# STM32H7A3 register map
File version: 3.4
CPU: CM7 r0p1, little endian, MPU, FPU, 4 interrupt priority bits
Registers are 32-bit, read-write, reset 0x0 unless marked. A register's access mark holds for its fields unless they carry their own. Offsets are from the block's base; [hi:lo] are bit positions; lines under a group give offsets from that group; {n}, {i} and the like mark numbered series; 'fields as' and 'values as' point back to an identical list.

## FLASH — Embedded Flash memory
Base 0x52002000
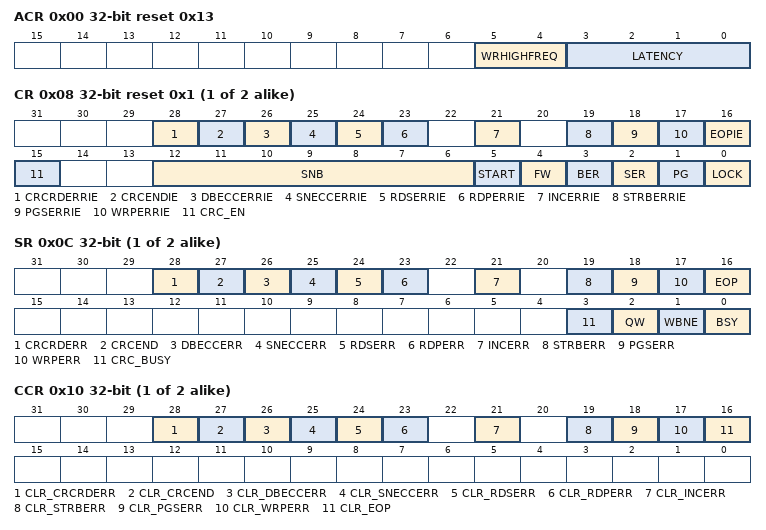
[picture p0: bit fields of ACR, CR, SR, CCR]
0x00 ACR reset 0x13 — Access control register
  [5:4] WRHIGHFREQ — Flash signal delay
  [3:0] LATENCY — Read latency
0x04 BANK{i} (i=1..2; step 0x100) group — Cluster BANK{i}, containing KEYR?, CR?, SR?, CCR?, PRAR_CUR?, PRAR_PRG?, SCAR_CUR?, SCAR_PRG?, WPSN_CUR?R, WPSN_PRG?R, CRCCR?, CRCSADD?R, CRCEADD?R, ECC_FA?R
  0x00 KEYR wo — FLASH key register for bank 1
    [31:0] KEY1R — Non-volatile memory bank 1 configuration access unlock key
  0x08 CR reset 0x1
    [28] CRCRDERRIE — Bank 1 CRC read error interrupt enable bit When CRCRDERRIE1 bit is set to 1, an interrupt is generated when a protected area (PCROP or secure-only) has been detected during the last CRC computation on bank 1. CRCRDERRIE1 can be programmed only when LOCK1 is cleared to 0.
    [27] CRCENDIE — Bank 1 CRC end of calculation interrupt enable bit When CRCENDIE1 bit is set to 1, an interrupt is generated when the CRC computation has completed on bank 1. CRCENDIE1 can be programmed only when LOCK1 is cleared to 0.
    [26] DBECCERRIE — Bank 1 ECC double detection error interrupt enable bit When DBECCERRIE1 bit is set to 1, an interrupt is generated when an ECC double detection error occurs during a read operation from bank 1. DBECCERRIE1 can be programmed only when LOCK1 is cleared to 0.
    [25] SNECCERRIE — Bank 1 ECC single correction error interrupt enable bit When SNECCERRIE1 bit is set to 1, an interrupt is generated when an ECC single correction error occurs during a read operation from bank 1. SNECCERRIE1 can be programmed only when LOCK1 is cleared to 0.
    [24] RDSERRIE — Bank 1 secure error interrupt enable bit When RDSERRIE1 bit is set to 1, an interrupt is generated when a secure error (access to a secure-only protected address) occurs during a read operation from bank 1. RDSERRIE1 can be programmed only when LOCK1 is cleared to 0.
    [23] RDPERRIE — Bank 1 read protection error interrupt enable bit When RDPERRIE1 bit is set to 1, an interrupt is generated when a read protection error occurs (access to an address protected by PCROP or by RDP level 1) during a read operation from bank 1. RDPERRIE1 can be programmed only when LOCK1 is cleared to 0.
    [21] INCERRIE — Bank 1 inconsistency error interrupt enable bit When INCERRIE1 bit is set to 1, an interrupt is generated when an inconsistency error occurs during a write operation to bank 1. INCERRIE1 can be programmed only when LOCK1 is cleared to 0.
    [19] STRBERRIE — Bank 1 strobe error interrupt enable bit When STRBERRIE1 bit is set to 1, an interrupt is generated when a strobe error occurs (the master programs several times the same byte in the write buffer) during a write operation to bank 1. STRBERRIE1 can be programmed only when LOCK1 is cleared to 0.
    [18] PGSERRIE — Bank 1 programming sequence error interrupt enable bit When PGSERRIE1 bit is set to 1, an interrupt is generated when a sequence error occurs during a program operation to bank 1. PGSERRIE1 can be programmed only when LOCK1 is cleared to 0.
    [17] WRPERRIE — Bank 1 write protection error interrupt enable bit When WRPERRIE1 bit is set to 1, an interrupt is generated when a protection error occurs during a program operation to bank 1. WRPERRIE1 can be programmed only when LOCK1 is cleared to 0.
    [16] EOPIE — Bank 1 end-of-program interrupt control bit Setting EOPIE1 bit to 1 enables the generation of an interrupt at the end of a program operation to bank 1. EOPIE1 can be programmed only when LOCK1 is cleared to 0.
    [15] CRC_EN — Bank 1 CRC control bit Setting CRC_EN bit to 1 enables the CRC calculation on bank 1. CRC_EN does not start CRC calculation but enables CRC configuration through FLASH_CRCCR1 register. When CRC calculation is performed on bank 1, it can only be disabled by setting CRC_EN bit to 0. Resetting CRC_EN clears CRC configuration and resets the content of FLASH_CRCDATAR register. Clearing CRC_EN to 0 sets CRCDATA to 0x0. CRC_EN can be programmed only when LOCK1 is cleared to 0.
    [12:6] SNB — Bank 1 sector erase selection number These bits are used to select the target sector for an erase operation (they are unused otherwise). SSN1 can be programmed only when LOCK1 is cleared to 0. .. ... ... Note: Bank 1 is limited to 16 and 64 sectors on STM32H7B0 and STM32H7A3xG devices, respectively.
    [5] START — Bank 1 erase start control bit START1 bit is used to start a sector erase or a bank erase operation. START1 can be programmed only when LOCK1 is cleared to 0. The embedded Flash memory resets START1 when the corresponding operation has been acknowledged. The user application cannot access any embedded Flash memory register until the operation is acknowledged.
    [4] FW — Bank 1 write forcing control bit FW1 forces a write operation even if the write buffer is not full. In this case all bits not written are set to 1 by hardware. FW1 can be programmed only when LOCK1 is cleared to 0. The embedded Flash memory resets FW1 when the corresponding operation has been acknowledged. Note: Using a force-write operation prevents the application from updating later the missing bits with something else than 1, because it is likely that it will lead to permanent ECC error. Write forcing is effective only if the write buffer is not empty (in particular, FW1 does not start several write operations when the force-write operations are performed consecutively).
    [3] BER — Bank 1 erase request Setting BER1 bit to 1 requests a bank erase operation on bank 1 (user Flash memory only). BER1 can be programmed only when LOCK1 is cleared to 0. BER1 has a higher priority than SER1: if both are set, the embedded Flash memory executes a bank erase. Note: Write protection error is triggered when a bank erase is required and some sectors are protected.
    [2] SER — Bank 1 sector erase request Setting SER1 bit to 1 requests a sector erase on bank 1. SER1 can be programmed only when LOCK1 is cleared to 0. BER1 has a higher priority than SER1: if both bits are set, the embedded Flash memory executes a bank erase. Note: Write protection error is triggered when a sector erase is required on a protected sector.
    [1] PG — Bank 1 internal buffer control bit Setting PG1 bit to 1 enables internal buffer for write operations to bank 1. This allows preparing program operations even if a sector or bank erase is ongoing. PG1 can be programmed only when LOCK1 is cleared to 0. When PG1 is reset, the internal buffer is disabled for write operations to bank 1, and all the data stored in the buffer but not sent to the operation queue are lost.
    [0] LOCK — Bank 1 configuration lock bit This bit locks the FLASH_CR1 register. The correct write sequence to FLASH_KEYR1 register unlocks this bit. If a wrong sequence is executed, or if the unlock sequence to FLASH_KEYR1 is performed twice, this bit remains locked until the next system reset. LOCK1 can be set by programming it to 1. When set to 1, a new unlock sequence is mandatory to unlock it. When LOCK1 changes from 0 to 1, the other bits of FLASH_CR1 register do not change.
  0x0C SR ro
    [28] CRCRDERR — Bank 1 CRC read error flag CRCRDERR1 flag is raised when a word is found read protected during a CRC operation on bank 1. An interrupt is generated if CRCRDIE1 and CRCEND1 are set to 1. Writing 1 to CLR_CRCRDERR1 bit in FLASH_CCR1 register clears CRCRDERR1. Note: This flag is valid only when CRCEND1 bit is set to 1
    [27] CRCEND — Bank 1 CRC end of calculation flag CRCEND1 bit is raised when the CRC computation has completed on bank 1. An interrupt is generated if CRCENDIE1 is set to 1. It is not necessary to reset CRCEND1 before restarting CRC computation. Writing 1 to CLR_CRCEND1 bit in FLASH_CCR1 register clears CRCEND1.
    [26] DBECCERR — Bank 1 ECC double detection error flag DBECCERR1 flag is raised when an ECC double detection error occurs during a read operation from bank 1. An interrupt is generated if DBECCERRIE1 is set to 1. Writing 1 to CLR_DBECCERR1 bit in FLASH_CCR1 register clears DBECCERR1.
    [25] SNECCERR — Bank 1 single correction error flag SNECCERR1 flag is raised when an ECC single correction error occurs during a read operation from bank 1. An interrupt is generated if SNECCERRIE1 is set to 1. Writing 1 to CLR_SNECCERR1 bit in FLASH_CCR1 register clears SNECCERR1.
    [24] RDSERR — Bank 1 secure error flag RDSERR1 flag is raised when a read secure error (read access to a secure-only protected word) occurs on bank 1. An interrupt is generated if RDSERRIE1 is set to 1. Writing 1 to CLR_RDSERR1 bit in FLASH_CCR1 register clears RDSERR1.
    [23] RDPERR — Bank 1 read protection error flag RDPERR1 flag is raised when an read protection error (read access to a PCROP-protected or a RDP-protected area) occurs on bank 1. An interrupt is generated if RDPERRIE1 is set to 1. Writing 1 to CLR_RDPERR1 bit in FLASH_CCR1 register clears RDPERR1.
    [21] INCERR — Bank 1 inconsistency error flag INCERR1 flag is raised when a inconsistency error occurs on bank 1. An interrupt is generated if INCERRIE1 is set to 1. Writing 1 to CLR_INCERR1 bit in the FLASH_CCR1 register clears INCERR1.
    [19] STRBERR — Bank 1 strobe error flag STRBERR1 flag is raised when a strobe error occurs on bank 1 (when the master attempts to write several times the same byte in the write buffer). An interrupt is generated if the STRBERRIE1 bit is set to 1. Writing 1 to CLR_STRBERR1 bit in FLASH_CCR1 register clears STRBERR1.
    [18] PGSERR — Bank 1 programming sequence error flag PGSERR1 flag is raised when a sequence error occurs on bank 1. An interrupt is generated if the PGSERRIE1 bit is set to 1. Writing 1 to CLR_PGSERR1 bit in FLASH_CCR1 register clears PGSERR1.
    [17] WRPERR — Bank 1 write protection error flag WRPERR1 flag is raised when a protection error occurs during a program operation to bank 1. An interrupt is also generated if the WRPERRIE1 is set to 1. Writing 1 to CLR_WRPERR1 bit in FLASH_CCR1 register clears WRPERR1.
    [16] EOP — Bank 1 end-of-program flag EOP1 flag is set when a programming operation to bank 1 completes. An interrupt is generated if the EOPIE1 is set to 1. It is not necessary to reset EOP1 before starting a new operation. EOP1 bit is cleared by writing 1 to CLR_EOP1 bit in FLASH_CCR1 register.
    [3] CRC_BUSY — Bank 1 CRC busy flag CRC_BUSY1 flag is set when a CRC calculation is ongoing on bank 1. This bit cannot be forced to 0. The user must wait until the CRC calculation has completed or disable CRC computation on bank 1.
    [2] QW — Bank 1 wait queue flag QW1 flag is set when a write, erase or option byte change operation is pending in the command queue buffer of bank 1. It is not possible to know what type of programming operation is present in the queue. This flag is reset by hardware when all write, erase or option byte change operations have been executed and thus removed from the waiting queue(s). This bit cannot be forced to 0. It is reset after a deterministic time if no other operations are requested.
    [1] WBNE — Bank 1 write buffer not empty flag WBNE1 flag is set when the embedded Flash memory is waiting for new data to complete the write buffer. In this state, the write buffer is not empty. WBNE1 is reset by hardware each time the write buffer is complete or the write buffer is emptied following one of the event below: the application software forces the write operation using FW1 bit in FLASH_CR1 the embedded Flash memory detects an error that involves data loss the application software has disabled write operations in this bank This bit cannot be forced to 0. To reset it, clear the write buffer by performing any of the above listed actions, or send the missing data.
    [0] BSY — Bank 1 busy flag BSY1 flag is set when an effective write, erase or option byte change operation is ongoing on bank 1. It is not possible to know what type of operation is being executed. BSY1 cannot be forced to 0. It is automatically reset by hardware every time a step in a write, erase or option byte change operation completes.
  0x10 CCR wo
    [28] CLR_CRCRDERR — Bank 1 CRCRDERR1 flag clear bit Setting this bit to 1 resets to 0 CRCRDERR1 flag in FLASH_SR1 register.
    [27] CLR_CRCEND — Bank 1 CRCEND1 flag clear bit Setting this bit to 1 resets to 0 CRCEND1 flag in FLASH_SR1 register.
    [26] CLR_DBECCERR — Bank 1 DBECCERR1 flag clear bit Setting this bit to 1 resets to 0 DBECCERR1 flag in FLASH_SR1 register. If the SNECCERR1 flag of FLASH_SR1 register is cleared to 0, FLASH_ECC_FA1R register is reset to 0 as well.
    [25] CLR_SNECCERR — Bank 1 SNECCERR1 flag clear bit Setting this bit to 1 resets to 0 SNECCERR1 flag in FLASH_SR1 register. If the DBECCERR1 flag of FLASH_SR1 register is cleared to 0, FLASH_ECC_FA1R register is reset to 0 as well.
    [24] CLR_RDSERR — Bank 1 RDSERR1 flag clear bit Setting this bit to 1 resets to 0 RDSERR1 flag in FLASH_SR1 register.
    [23] CLR_RDPERR — Bank 1 RDPERR1 flag clear bit Setting this bit to 1 resets to 0 RDPERR1 flag in FLASH_SR1 register.
    [21] CLR_INCERR — Bank 1 INCERR1 flag clear bit Setting this bit to 1 resets to 0 INCERR1 flag in FLASH_SR1 register.
    [19] CLR_STRBERR — Bank 1 STRBERR1 flag clear bit Setting this bit to 1 resets to 0 STRBERR1 flag in FLASH_SR1 register.
    [18] CLR_PGSERR — Bank 1 PGSERR1 flag clear bit Setting this bit to 1 resets to 0 PGSERR1 flag in FLASH_SR1 register.
    [17] CLR_WRPERR — Bank 1 WRPERR1 flag clear bit Setting this bit to 1 resets to 0 WRPERR1 flag in FLASH_SR1 register.
    [16] CLR_EOP — Bank 1 EOP1 flag clear bit Setting this bit to 1 resets to 0 EOP1 flag in FLASH_SR1 register.
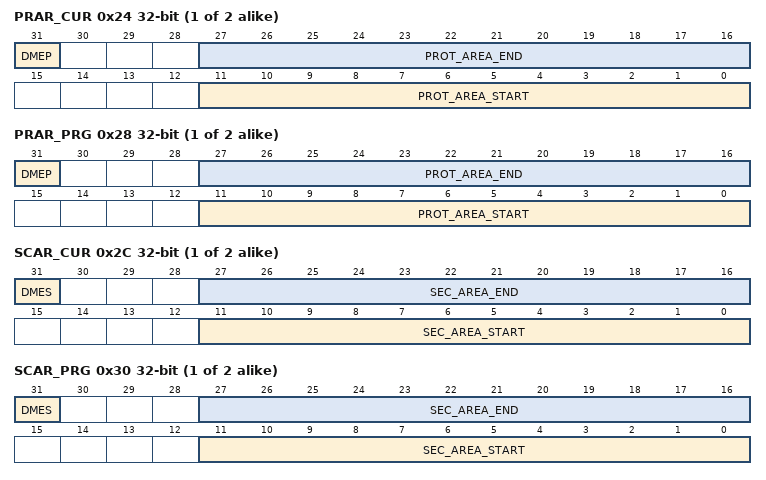
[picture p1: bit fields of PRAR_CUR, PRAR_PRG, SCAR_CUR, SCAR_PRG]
  0x24 PRAR_CUR ro (reset mask 0xF000) — FLASH protection address for bank 1
    [31] DMEP — Bank 1 PCROP protected erase enable option status bit If DMEP1 is set to 1, the PCROP protected area in bank 1 is erased when a protection level regression (change from level 1 to 0) or a bank erase with protection removal occurs.
    [27:16] PROT_AREA_END — Bank 1 PCROP area end status bits These bits contain the last 256-byte block of the PCROP area in bank 1. If this address is equal to PROT_AREA_START1, the whole bank 1 is PCROP protected. If this address is lower than PROT_AREA_START1, no protection is set on bank 1.
    [11:0] PROT_AREA_START — Bank 1 PCROP area start status bits These bits contain the first 256-byte block of the PCROP area in bank 1. If this address is equal to PROT_AREA_END1, the whole bank 1 is PCROP protected. If this address is higher than PROT_AREA_END1, no protection is set on bank 1.
  0x28 PRAR_PRG (reset mask 0xF000) — FLASH protection address for bank 1
    [31] DMEP — Bank 1 PCROP protected erase enable option configuration bit If DMEP1 is set to 1, the PCROP protected area in bank 1 is erased when a protection level regression (change from level 1 to 0) or a bank erase with protection removal occurs.
    [27:16] PROT_AREA_END — Bank 1 PCROP area end configuration bits These bits contain the last 256-byte block of the PCROP area in bank 1. If this address is equal to PROT_AREA_START1, the whole bank 1 is PCROP protected. If this address is lower than PROT_AREA_START1, no protection is set on bank 1.
    [11:0] PROT_AREA_START — Bank 1 PCROP area start configuration bits These bits contain the first 256-byte block of the PCROP area in bank 1. If this address is equal to PROT_AREA_END1, the whole bank 1 is PCROP protected. If this address is higher than PROT_AREA_END1, no protection is set on bank 1.
  0x2C SCAR_CUR ro (reset mask 0xF000) — FLASH secure address for bank 1
    [31] DMES — Bank 1 secure access protected erase enable option status bit If DMES1 is set to 1, the secure access only area in bank 1 is erased when a protection level regression (change from level 1 to 0) or a bank erase with protection removal occurs.
    [27:16] SEC_AREA_END — Bank 1 secure-only area end status bits These bits contain the last 256-byte block of the secure-only area in bank 1. If this address is equal to SEC_AREA_START1, the whole bank 1 is secure access only. If this address is lower than SEC_AREA_START1, no protection is set on bank 1.
    [11:0] SEC_AREA_START — Bank 1 secure-only area start status bits These bits contain the first 256 bytes of block of the secure-only area in bank 1. If this address is equal to SEC_AREA_END1, the whole bank 1 is secure access only. If this address is higher than SEC_AREA_END1, no protection is set on bank 1.
  0x30 SCAR_PRG (reset mask 0xF000) — FLASH secure address for bank 1
    [31] DMES — Bank 1 secure access protected erase enable option configuration bit If DMES1 is set to 1, the secure access only area in bank 1 is erased when a protection level regression (change from level 1 to 0) or a bank erase with protection removal occurs.
    [27:16] SEC_AREA_END — Bank 1 secure-only area end configuration bits These bits contain the last block of 256 bytes of the secure-only area in bank 1. If this address is equal to SEC_AREA_START1, the whole bank 1 is secure access only. If this address is lower than SEC_AREA_START1, no protection is set on bank 1.
    [11:0] SEC_AREA_START — Bank 1 secure-only area start configuration bits These bits contain the first block of 256 bytes of the secure-only area in bank 1. If this address is equal to SEC_AREA_END1, the whole bank 1 is secure access only. If this address is higher than SEC_AREA_END1, no protection is set on bank 1.
  0x34 WPSN_CURR ro reset not defined — FLASH write sector group protection for bank 1
    [31:0] WRPSGn — Bank 1 sector group protection option status byte Each FLASH_WPSGN_CUR1R bit reflects the write protection status of the corresponding group of four consecutive sectors in bank 1 (0: the group is write protected; 1: the group is not write protected) Bit 0: Group embedding sectors 0 to 3 Bit 1: Group embedding sectors 4 to 7 Bit N: Group embedding sectors 4 x N to 4 x N + 3 Bit 31: Group embedding sectors 124 to 127 Note: Bank 1 is limited to 16 and 64 sectors on STM32H7B0 and STM32H7A3xG devices, respectively.
  0x38 WPSN_PRGR reset not defined — FLASH write sector group protection for bank 1
    [31:0] WRPSGn — Bank 1 sector group protection option status byte Setting WRPSGn1 bits to 0 write protects the corresponding group of four consecutive sectors in bank 1 (0: the group is write protected; 1: the group is not write protected) Bit 0: Group embedding sectors 0 to 3 Bit 1: Group embedding sectors 4 to 7 Bit N: Group embedding sectors 4 x N to 4 x N + 3 Bit 31: Group embedding sectors 124 to 127 Note: Bank 1 is limited to 16 and 64 sectors on STM32H7B0 and STM32H7A3xG devices, respectively.
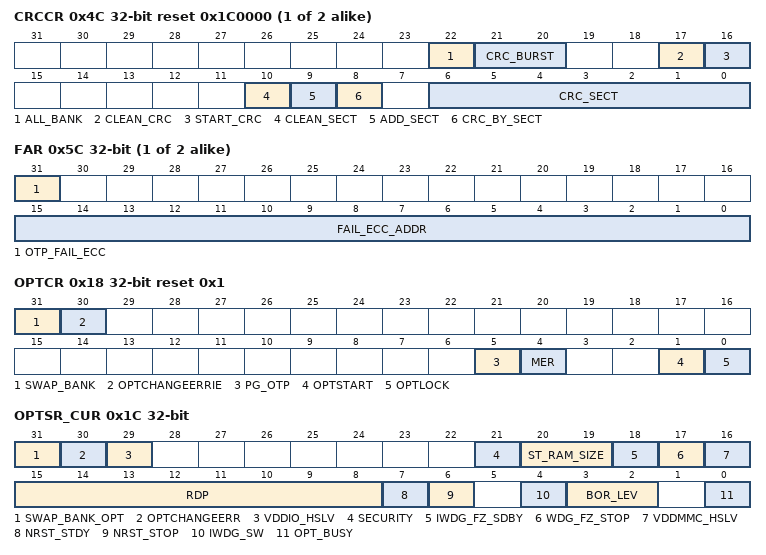
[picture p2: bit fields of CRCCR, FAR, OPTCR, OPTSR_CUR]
  0x4C CRCCR access per field reset 0x1C0000 — FLASH CRC control register for bank 1
    [22] ALL_BANK wo — Bank 1 CRC select bit When ALL_BANK is set to 1, all bank 1 user sectors are added to list of sectors on which the CRC is calculated.
    [21:20] CRC_BURST rw — Bank 1 CRC burst size CRC_BURST bits set the size of the bursts that are generated by the CRC calculation unit.
    [17] CLEAN_CRC wo — Bank 1 CRC clear bit Setting CLEAN_CRC to 1 clears the current CRC result stored in the FLASH_CRCDATAR register.
    [16] START_CRC rw — Bank 1 CRC start bit START_CRC bit triggers a CRC calculation on bank 1 using the current configuration. No CRC calculation can launched when an option byte change operation is ongoing because all write accesses to embedded Flash memory registers are put on hold until the option byte change operation has completed.
    [10] CLEAN_SECT wo — Bank 1 CRC sector list clear bit Setting CLEAN_SECT to 1 clears the list of sectors on which the CRC is calculated.
    [9] ADD_SECT wo — Bank 1 CRC sector select bit Setting ADD_SECT to 1 adds the sector whose number is CRC_SECT to the list of sectors on which the CRC is calculated.
    [8] CRC_BY_SECT rw — Bank 1 CRC sector mode select bit When CRC_BY_SECT is set to 1, the CRC calculation is performed at sector level, on the sectors present in the list of sectors. To add a sector to this list, use ADD_SECT and CRC_SECT bits. To clean the list, use CLEAN_SECT bit. When CRC_BY_SECT is reset to 0, the CRC calculation is performed on all addresses between CRC_START_ADDR and CRC_END_ADDR.
    [6:0] CRC_SECT rw — Bank 1 CRC sector number CRC_SECT is used to select one user Flash sectors to be added to the list of sectors on which the CRC is calculated. The CRC can be computed either between two addresses (using registers FLASH_CRCSADD1R and FLASH_CRCEADD1R) or on a list of sectors using this register. If this latter option is selected, it is possible to add a sector to the list of sectors by programming the sector number in CRC_SECT and then setting to 1 ADD_SECT. The list of sectors can be erased either by setting CLEAN_SECT bit or by disabling the CRC computation. CRC_SECT can be set only when CRC_EN of FLASH_CR register is set to 1. ... ... ... Note: Bank 1 is limited to 16 and 64 sectors on STM32H7B0 and STM32H7AxG devices, respectively.
  0x50 CRCSADDR
    [19:2] CRC_START_ADDR — CRC start address on bank 1 CRC_START_ADDR is used when CRC_BY_SECT is cleared to 0. It must be programmed to the start address of the bank 1 memory area on which the CRC calculation is performed.
  0x54 CRCEADDR
    [19:2] CRC_END_ADDR — CRC end address on bank 1 CRC_END_ADDR is used when CRC_BY_SECT is cleared to 0. It must be programmed to the end address of the bank 1 memory area on which the CRC calculation is performed
  0x5C FAR ro
    [31] OTP_FAIL_ECC — OTP ECC error bit This bit is set to 1 when one single ECC correction or double ECC detection occurred during the last successful read operation from the read-only/ OTP area. The address of the ECC error is available in FAIL_ECC_ADDR1 bitfield.
    [15:0] FAIL_ECC_ADDR — Bank 1 ECC error address When an ECC error occurs (both for single correction or double detection) during a read operation from bank 1, the FAIL_ECC_ADDR1 bitfield contains the address that generated the error. FAIL_ECC_ADDR1 is reset when the flag error in the FLASH_SR1 register (CLR_SNECCERR1 or CLR_DBECCERR1) is reset. The embedded Flash memory programs the address in this register only when no ECC error flags are set. This means that only the first address that generated an ECC error is saved. The address in FAIL_ECC_ADDR1 is relative to the Flash memory area where the error occurred (user Flash memory, system Flash memory, read-only/OTP area).
0x08 OPTKEYR wo — FLASH option key register
  [31:0] OPTKEYR — Unlock key option bytes
0x18 OPTCR reset 0x1 — FLASH option control register
  [31] SWAP_BANK ro — Bank swapping configuration bit
  [30] OPTCHANGEERRIE — Option byte change error interrupt enable bit
  [5] PG_OTP — OTP program control bit
  [4] MER wo — Flash mass erase enable bit
  [1] OPTSTART wo — Option byte start change option configuration bit
  [0] OPTLOCK — FLASH_OPTCR lock option configuration bit
0x1C OPTSR_CUR — FLASH option status register
  [31] SWAP_BANK_OPT — Bank swapping option status bit
  [30] OPTCHANGEERR — Option byte change error flag
  [29] VDDIO_HSLV — I/O high-speed at low-voltage status bit (PRODUCT_BELOW_25V)
  [21] SECURITY — Security enable option status bit
  [20:19] ST_RAM_SIZE — DTCM RAM size option status
  [18] IWDG_FZ_SDBY — IWDG Standby mode freeze option status bit
  [17] WDG_FZ_STOP — IWDG Stop mode freeze option status bit
  [16] VDDMMC_HSLV — IWDG Stop mode freeze option status bit
  [15:8] RDP — Readout protection level option status byte
  [7] NRST_STDY — D1 DStandby entry reset option status bit
  [6] NRST_STOP — D1 DStop entry reset option status bit
  [4] IWDG_SW — IWDG1 control option status bit
  [3:2] BOR_LEV — Brownout level option status bit
  [0] OPT_BUSY — Option byte change ongoing flag
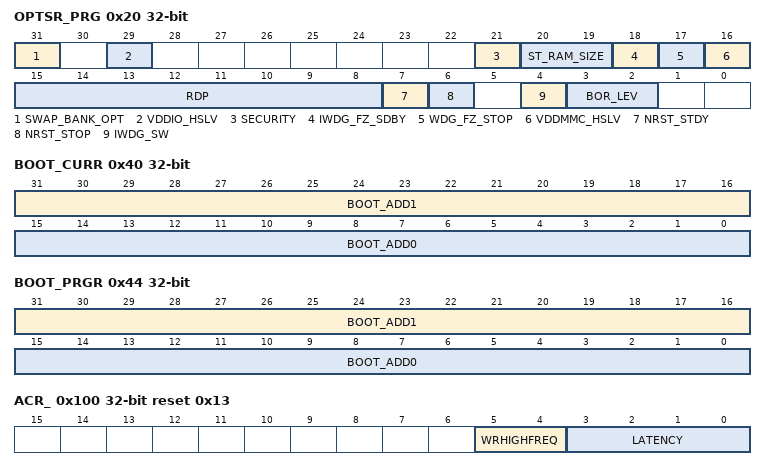
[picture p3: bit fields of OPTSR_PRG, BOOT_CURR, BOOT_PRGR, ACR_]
0x20 OPTSR_PRG — FLASH option status register
  [31] SWAP_BANK_OPT — Bank swapping option configuration bit
  [29] VDDIO_HSLV
  [21] SECURITY — Security option configuration bit
  [20:19] ST_RAM_SIZE — DTCM size select option configuration bits
  [18] IWDG_FZ_SDBY — IWDG Standby mode freeze option configuration bit
  [17] WDG_FZ_STOP — IWDG Stop mode freeze option configuration bit
  [16] VDDMMC_HSLV
  [15:8] RDP — Readout protection level option configuration byte
  [7] NRST_STDY — Option byte erase after D1 DStandby option configuration bit
  [6] NRST_STOP — Option byte erase after D1 DStop option configuration bit
  [4] IWDG_SW — IWDG1 option configuration bit
  [3:2] BOR_LEV — BOR reset level option configuration bits
0x24 OPTCCR wo — FLASH option clear control register
  [30] CLR_OPTCHANGEERR — OPTCHANGEERR reset bit
0x40 BOOT_CURR ro — FLASH register with boot address
  [31:16] BOOT_ADD1 — Boot address 1
  [15:0] BOOT_ADD0 — Boot address 0
0x44 BOOT_PRGR ro — FLASH register with boot address
  fields as BOOT_CURR
0x5C CRCDATAR — FLASH CRC data register
  [31:0] CRC_DATA — CRC result
0x68 OTPBL_CUR ro reset not defined — FLASH OTP block lock
  [15:0] LOCKBL — OTP Block Lock Block n corresponds to OTP 16-bit word 32 x n to 32 x n + 31. LOCKBL[n] = 1 indicates that all OTP 16-bit words in OTP Block n are locked and can no longer be programmed. LOCKBL[n] = 0 indicates that all OTP 16-bit words in OTP Block n are not locked and can still be modified.
0x6C OTPBL_PRG reset not defined — FLASH OTP block lock
  [15:0] LOCKBL — OTP Block Lock Block n corresponds to OTP 16-bit word 32 x n to 32 x n + 31. LOCKBL[n] = 1 indicates that all OTP 16-bit words in OTP Block n are locked and can no longer be programmed. LOCKBL[n] = 0 indicates that all OTP 16-bit words in OTP Block n are not locked and can still be modified. LOCKBL bits can be set if the corresponding bit in FLASH_OTPBL_CUR is cleared.
0x100 ACR_ reset 0x13 — Access control register
  [5:4] WRHIGHFREQ — Flash signal delay
  [3:0] LATENCY — Read latency
0x108 OPTKEYR_ — FLASH option key register
  [31:0] OPTKEYR — Unlock key option bytes
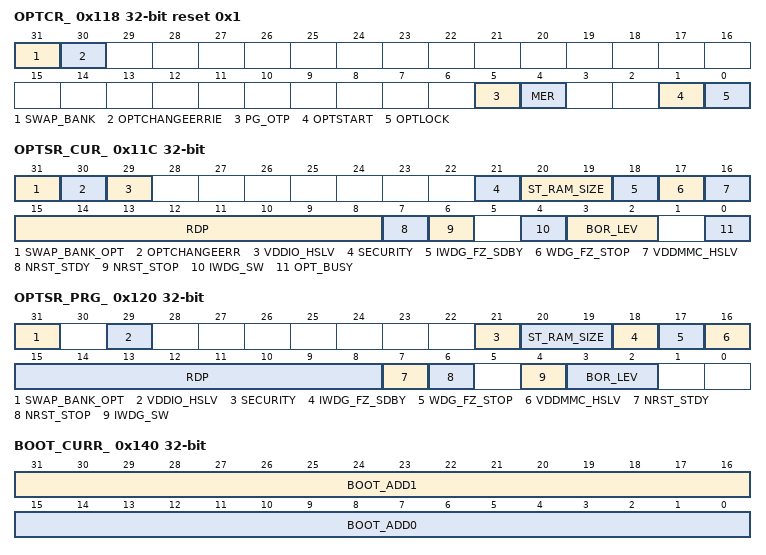
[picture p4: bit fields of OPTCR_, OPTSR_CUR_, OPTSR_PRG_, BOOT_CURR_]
0x118 OPTCR_ reset 0x1 — FLASH option control register
  fields as OPTCR
0x11C OPTSR_CUR_ — FLASH option status register
  fields as OPTSR_CUR
0x120 OPTSR_PRG_ — FLASH option status register
  fields as OPTSR_PRG
0x124 OPTCCR_ wo — FLASH option clear control register
  [30] CLR_OPTCHANGEERR — OPTCHANGEERR reset bit
0x140 BOOT_CURR_ ro — FLASH register with boot address
  fields as BOOT_CURR
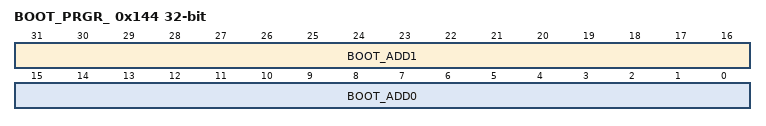
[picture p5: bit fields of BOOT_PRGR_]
0x144 BOOT_PRGR_ ro — FLASH register with boot address
  fields as BOOT_CURR
